# MSPM0G310X register map
Vendor: Texas Instruments; File version: This preliminary header file does not have a version number - build date: 2024-04-29 21:43:54
ARM Device
CPU: CM0 r0p1, little endian, MPU, no FPU, 3 interrupt priority bits
Registers are 32-bit, read-write, reset 0x0 unless marked. A register's access mark holds for its fields unless they carry their own. Offsets are from the block's base; lines under a group give offsets from that group; [hi:lo] are bit positions; {n}, {i} and the like mark numbered series; 'fields as' and 'values as' point back to an identical list; <NAME> marks a mode.

## Memory map
0x00000000 FLASH size 0x20000 — MEM
0x20000000 SYSMEM size 0x8000 — MEM
0x40000000 ADC0 size 0x2000 — PERIPHERALREGION
0x40002000 ADC1 size 0x2000 — PERIPHERALREGION
0x40030000 VREF size 0x1F00 — PERIPHERALREGION
0x40080000 WWDT0 size 0x1500 — WWDT
0x40082000 WWDT1 size 0x1500 — WWDT
0x40084000 TIMG0 size 0x1F00 — PERIPHERALREGION
0x40090000 TIMG8 size 0x1F00 — PERIPHERALREGION
0x40094000 RTC size 0x1200 — PERIPHERALREGION
0x400A0000 GPIOA size 0x1F00 — PERIPHERALREGION
0x400A2000 GPIOB size 0x1F00 — PERIPHERALREGION
0x400AF000 SYSCTL size 0x2C64 — mem_map
0x400C7000 DEBUGSS size 0x1F00 — DSSM
0x400C9000 EVENTLP size 0x3000 — PERIPHERALREGION
0x400CD000 FLASHCTL size 0x2000 — F65NW
0x400F0000 I2C0 size 0x1F00 — PERIPHERALREGION
0x400F2000 I2C1 size 0x1F00 — PERIPHERALREGION
0x40100000 UART1 size 0x1F00 — PERIPHERALREGION
0x40102000 UART2 size 0x1F00 — PERIPHERALREGION
0x40108000 UART0 size 0x1F00 — PERIPHERALREGION
0x40400000 CPUSS size 0x1F00 — CPUSSMMR
0x40424000 WUC size 0x500 — PERIPHERALREGION
0x40428000 IOMUX size 0x2000 — PERIPHERALREGION
0x4042A000 DMA size 0x1F00 — PERIPHERALREGION
0x40440000 CRC size 0x2000 — PERIPHERALREGION
0x40442000 AES size 0x1F00 — PERIPHERALREGION
0x40444000 TRNG size 0x1E00 — PERIPHERALREGION
0x40468000 SPI0 size 0x1F00 — PERIPHERALREGION
0x4046A000 SPI1 size 0x1F00 — PERIPHERALREGION
0x40500000 UART3 size 0x1F00 — PERIPHERALREGION
0x40508000 CANFD0 size 0x8000 — PERIPHERALREGION
0x40556000 ADC0_SVT size 0x1000 — PERIPHERALREGIONSVT
0x40558000 ADC1_SVT size 0x1000 — PERIPHERALREGIONSVT
0x40860000 TIMA0 size 0x1F00 — PERIPHERALREGION
0x40862000 TIMA1 size 0x1F00 — PERIPHERALREGION
0x40868000 TIMG6 size 0x1F00 — PERIPHERALREGION
0x4086A000 TIMG7 size 0x1F00 — PERIPHERALREGION
0x40870000 TIMG12 size 0x1F00 — PERIPHERALREGION

## CANFD0 (part 1 of 3) — PERIPHERALREGION
Base 0x40508000
0x6800 CANFD0_PWREN — Power enable
  [0] ENABLE — Enable the power
    0=DISABLE (Disable Power); 1=ENABLE (Enable Power)
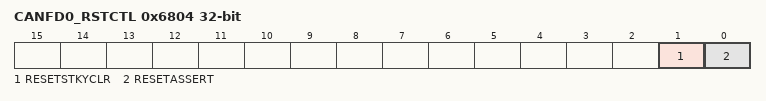
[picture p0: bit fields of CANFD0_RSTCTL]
0x6804 CANFD0_RSTCTL wo — Reset Control
  [1] RESETSTKYCLR — Clear the RESETSTKY bit in the STAT register
    0=NOP (Writing 0 has no effect); 1=CLR (Clear reset sticky bit)
  [0] RESETASSERT — Assert reset to the peripheral
    0=NOP (Writing 0 has no effect); 1=ASSERT (Assert reset)
0x6814 CANFD0_STAT ro — Status Register
  [16] RESETSTKY — This bit indicates, if the peripheral was reset, since this bit was cleared by RESETSTKYCLR in the RSTCTL register
    0=NORES (The peripheral has not been reset since this bit was last cleared by RESETSTKYCLR in the RSTCTL register); 1=RESET (The peripheral was reset since the last bit clear)

## Licence text in the file
Copyright (C) 2024 Texas Instruments Incorporated - http://www.ti.com/ Redistribution and use in source and binary forms, with or without modification, are permitted provided that the following conditions are met: Redistributions of source code must retain the above copyright notice, this list of conditions and the following disclaimer. Redistributions in binary form must reproduce the above copyright notice, this list of conditions and the following disclaimer in the documentation and/or other materials provided with the distribution. Neither the name of Texas Instruments Incorporated nor the names of its contributors may be used to endorse or promote products derived from this software without specific prior written permission. THIS SOFTWARE IS PROVIDED BY THE COPYRIGHT HOLDERS AND CONTRIBUTORS "AS IS" AND ANY EXPRESS OR IMPLIED WARRANTIES, INCLUDING, BUT NOT LIMITED TO, THE IMPLIED WARRANTIES OF MERCHANTABILITY AND FITNESS FOR A PARTICULAR PURPOSE ARE DISCLAIMED. IN NO EVENT SHALL THE COPYRIGHT OWNER OR CONTRIBUTORS BE LIABLE FOR ANY DIRECT, INDIRECT, INCIDENTAL, SPECIAL, EXEMPLARY, OR CONSEQUENTIAL DAMAGES (INCLUDING, BUT NOT LIMITED TO, PROCUREMENT OF SUBSTITUTE GOODS OR SERVICES; LOSS OF USE, DATA, OR PROFITS; OR BUSINESS INTERRUPTION) HOWEVER CAUSED AND ON ANY THEORY OF LIABILITY, WHETHER IN CONTRACT, STRICT LIABILITY, OR TORT (INCLUDING NEGLIGENCE OR OTHERWISE) ARISING IN ANY WAY OUT OF THE USE OF THIS SOFTWARE, EVEN IF ADVISED OF THE POSSIBILITY OF SUCH DAMAGE.
